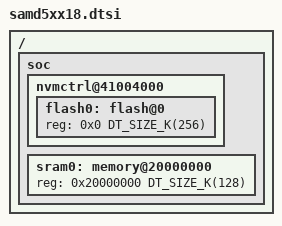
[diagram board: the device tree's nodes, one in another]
/*
 * Copyright (c) 2019 ML!PA Consulting GmbH
 *
 * SPDX-License-Identifier: Apache-2.0
 */

#include <mem.h>
#include <atmel/samd5x.dtsi>

/ {
	soc {
		nvmctrl@41004000 {
			flash0: flash@0 {
				reg = <0x0 DT_SIZE_K(256)>;
			};
		};

		sram0: memory@20000000 {
			reg = <0x20000000 DT_SIZE_K(128)>;
		};
	};
};
